VERSION ""

NS_ :

BS_:

BU_: AMK1 AMK0 VCU

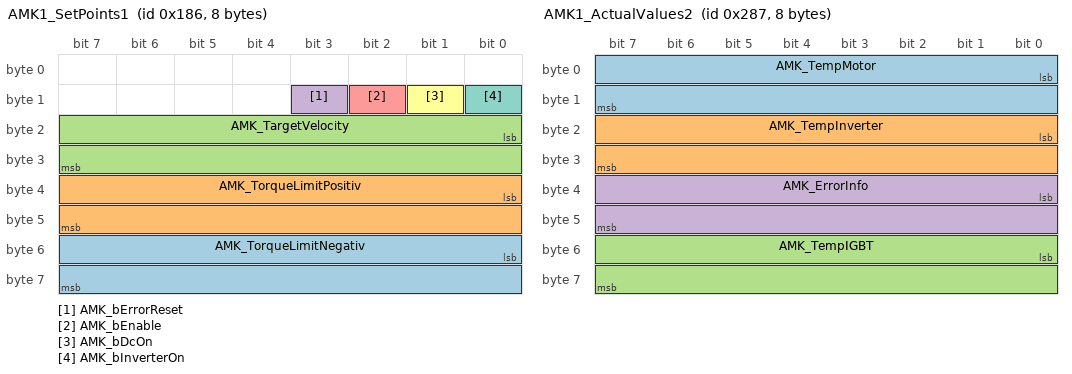
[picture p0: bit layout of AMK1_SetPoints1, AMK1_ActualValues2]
BO_ 390 AMK1_SetPoints1: 8 VCU
 SG_ AMK_TorqueLimitNegativ : 48|16@1- (1,0) [0|0] "0.1%Mn"  AMK1
 SG_ AMK_TorqueLimitPositiv : 32|16@1- (1,0) [0|0] "0.1%Mn"  AMK1
 SG_ AMK_TargetVelocity : 16|16@1- (1,0) [0|0] "rpm"  AMK1
 SG_ AMK_bErrorReset : 11|1@1+ (1,0) [0|0] ""  AMK1
 SG_ AMK_bEnable : 10|1@1+ (1,0) [0|0] ""  AMK1
 SG_ AMK_bDcOn : 9|1@1+ (1,0) [0|0] ""  AMK1
 SG_ AMK_bInverterOn : 8|1@1+ (1,0) [0|0] ""  AMK1

BO_ 647 AMK1_ActualValues2: 8 AMK1
 SG_ AMK_TempMotor : 0|16@1- (0.1,0) [-3276.8|3276.7] "°C"  VCU
 SG_ AMK_TempInverter : 16|16@1- (0.1,0) [-3276.8|3276.7] "°C"  VCU
 SG_ AMK_TempIGBT : 48|16@1- (0.1,0) [-3276.8|3276.7] "°C"  VCU
 SG_ AMK_ErrorInfo : 32|16@1+ (1,0) [0|65535] ""  VCU

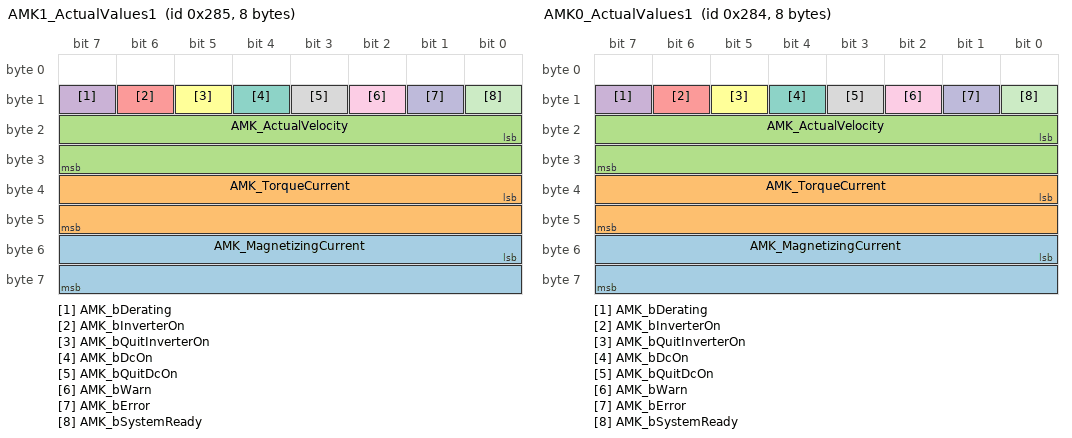
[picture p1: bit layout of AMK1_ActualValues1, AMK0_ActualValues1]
BO_ 645 AMK1_ActualValues1: 8 AMK1
 SG_ AMK_MagnetizingCurrent : 48|16@1- (1,0) [0|0] ""  VCU
 SG_ AMK_TorqueCurrent : 32|16@1- (1,0) [0|0] ""  VCU
 SG_ AMK_ActualVelocity : 16|16@1- (1,0) [0|0] "rpm"  VCU
 SG_ AMK_bDerating : 15|1@1+ (1,0) [0|0] ""  VCU
 SG_ AMK_bInverterOn : 14|1@1+ (1,0) [0|0] ""  VCU
 SG_ AMK_bQuitInverterOn : 13|1@1+ (1,0) [0|0] ""  VCU
 SG_ AMK_bDcOn : 12|1@1+ (1,0) [0|0] ""  VCU
 SG_ AMK_bQuitDcOn : 11|1@1+ (1,0) [0|0] ""  VCU
 SG_ AMK_bWarn : 10|1@1+ (1,0) [0|0] ""  VCU
 SG_ AMK_bError : 9|1@1+ (1,0) [0|0] ""  VCU
 SG_ AMK_bSystemReady : 8|1@1+ (1,0) [0|0] ""  VCU

BO_ 644 AMK0_ActualValues1: 8 AMK0
 SG_ AMK_MagnetizingCurrent : 48|16@1- (1,0) [0|0] ""  VCU
 SG_ AMK_TorqueCurrent : 32|16@1- (1,0) [0|0] ""  VCU
 SG_ AMK_ActualVelocity : 16|16@1- (1,0) [0|0] "rpm"  VCU
 SG_ AMK_bDerating : 15|1@1+ (1,0) [0|0] ""  VCU
 SG_ AMK_bInverterOn : 14|1@1+ (1,0) [0|0] ""  VCU
 SG_ AMK_bQuitInverterOn : 13|1@1+ (1,0) [0|0] ""  VCU
 SG_ AMK_bDcOn : 12|1@1+ (1,0) [0|0] ""  VCU
 SG_ AMK_bQuitDcOn : 11|1@1+ (1,0) [0|0] ""  VCU
 SG_ AMK_bWarn : 10|1@1+ (1,0) [0|0] ""  VCU
 SG_ AMK_bError : 9|1@1+ (1,0) [0|0] ""  VCU
 SG_ AMK_bSystemReady : 8|1@1+ (1,0) [0|0] ""  VCU

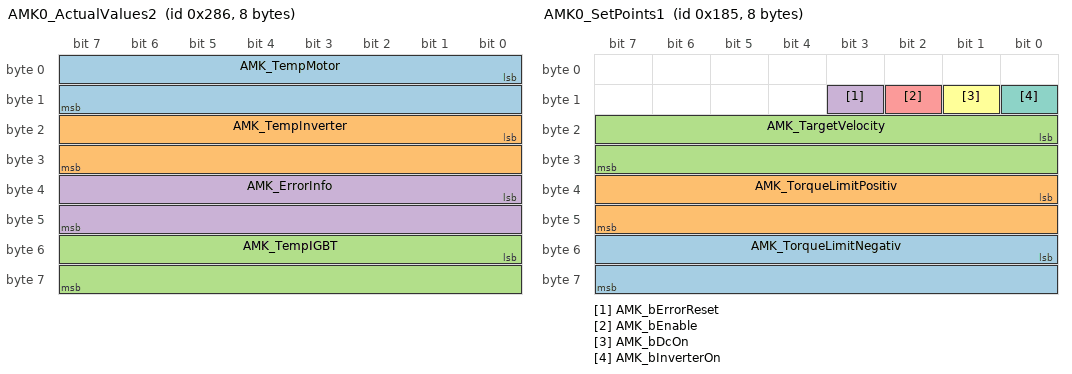
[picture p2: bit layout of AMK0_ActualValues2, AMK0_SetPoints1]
BO_ 646 AMK0_ActualValues2: 8 AMK0
 SG_ AMK_TempMotor : 0|16@1- (0.1,0) [-3276.8|3276.7] "°C"  VCU
 SG_ AMK_TempInverter : 16|16@1- (0.1,0) [-3276.8|3276.7] "°C"  VCU
 SG_ AMK_TempIGBT : 48|16@1- (0.1,0) [-3276.8|3276.7] "°C"  VCU
 SG_ AMK_ErrorInfo : 32|16@1+ (1,0) [0|65535] ""  VCU

BO_ 389 AMK0_SetPoints1: 8 VCU
 SG_ AMK_TorqueLimitNegativ : 48|16@1- (1,0) [0|0] "0.1%Mn"  AMK0
 SG_ AMK_TorqueLimitPositiv : 32|16@1- (1,0) [0|0] "0.1%Mn"  AMK0
 SG_ AMK_TargetVelocity : 16|16@1- (1,0) [0|0] "rpm"  AMK0
 SG_ AMK_bErrorReset : 11|1@1+ (1,0) [0|0] ""  AMK0
 SG_ AMK_bEnable : 10|1@1+ (1,0) [0|0] ""  AMK0
 SG_ AMK_bDcOn : 9|1@1+ (1,0) [0|0] ""  AMK0
 SG_ AMK_bInverterOn : 8|1@1+ (1,0) [0|0] ""  AMK0

BA_DEF_ BO_  "GenMsgCycleTime" INT 0 10000;
BA_DEF_  "BusType" STRING ;
BA_DEF_DEF_  "GenMsgCycleTime" 0;
BA_DEF_DEF_  "BusType" "";
BA_ "BusType" "CAN";
BA_ "GenMsgCycleTime" BO_ 390 5;
BA_ "GenMsgCycleTime" BO_ 647 5;
BA_ "GenMsgCycleTime" BO_ 645 5;
BA_ "GenMsgCycleTime" BO_ 644 5;
BA_ "GenMsgCycleTime" BO_ 646 5;
BA_ "GenMsgCycleTime" BO_ 389 5;
